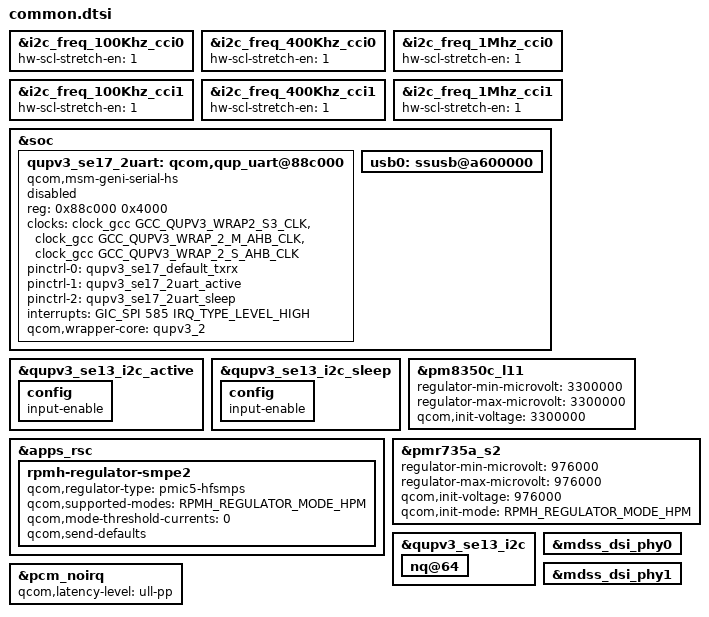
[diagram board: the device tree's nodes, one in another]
/*
 * Common dtsi changes for Asus lahaina platform
 */

#include "common-memory.dtsi"
#include "common-pinctrl.dtsi"

&i2c_freq_100Khz_cci0 {
	hw-scl-stretch-en = <1>;
};

&i2c_freq_400Khz_cci0 {
	hw-scl-stretch-en = <1>;
};

&i2c_freq_1Mhz_cci0 {
	hw-scl-stretch-en = <1>;
};

&i2c_freq_100Khz_cci1 {
	hw-scl-stretch-en = <1>;
};

&i2c_freq_400Khz_cci1 {
	hw-scl-stretch-en = <1>;
};

&i2c_freq_1Mhz_cci1 {
	hw-scl-stretch-en = <1>;
};

&soc {
	qupv3_se17_2uart: qcom,qup_uart@88c000 {
		compatible = "qcom,msm-geni-serial-hs";
		reg = <0x88c000 0x4000>;
		reg-names = "se_phys";
		clock-names = "se-clk", "m-ahb", "s-ahb";
		clocks = <&clock_gcc GCC_QUPV3_WRAP2_S3_CLK>,
		<&clock_gcc GCC_QUPV3_WRAP_2_M_AHB_CLK>,
		<&clock_gcc GCC_QUPV3_WRAP_2_S_AHB_CLK>;
		pinctrl-names = "default", "active", "sleep";
		pinctrl-0 = <&qupv3_se17_default_txrx>;
		pinctrl-1 = <&qupv3_se17_2uart_active>;
		pinctrl-2 = <&qupv3_se17_2uart_sleep>;
		interrupts = <GIC_SPI 585 IRQ_TYPE_LEVEL_HIGH>;
		qcom,wrapper-core = <&qupv3_2>;
		status = "disabled";
	};

	usb0: ssusb@a600000 {
		/delete-property/ extcon;
	};
};

&qupv3_se13_i2c_active {
	config {
		input-enable;
	};
};

&qupv3_se13_i2c_sleep {
	config {
		input-enable;
	};
};

&pm8350c_l11 {
	regulator-min-microvolt = <3300000>;
	regulator-max-microvolt = <3300000>;
	qcom,init-voltage = <3300000>;
};

&apps_rsc {
	rpmh-regulator-smpe2 {
		qcom,regulator-type = "pmic5-hfsmps";
		qcom,supported-modes = <RPMH_REGULATOR_MODE_HPM>;
		qcom,mode-threshold-currents = <0>;
		qcom,send-defaults;
	};
};

&pmr735a_s2 {
	regulator-min-microvolt = <976000>;
	regulator-max-microvolt = <976000>;
	qcom,init-voltage = <976000>;
	qcom,init-mode = <RPMH_REGULATOR_MODE_HPM>;
};

&qupv3_se13_i2c {
	nq@64 {
		/delete-property/ vdd-supply;
		/delete-property/ rtc6226,vdd-supply-voltage;
	};
};

&pcm_noirq {
	qcom,latency-level = "ull-pp";
};

&mdss_dsi_phy0 {
	/delete-property/ qcom,dsi-pll-ssc-en;
	/delete-property/ qcom,dsi-pll-ssc-mode;
};

&mdss_dsi_phy1 {
	/delete-property/ qcom,dsi-pll-ssc-en;
	/delete-property/ qcom,dsi-pll-ssc-mode;
};
